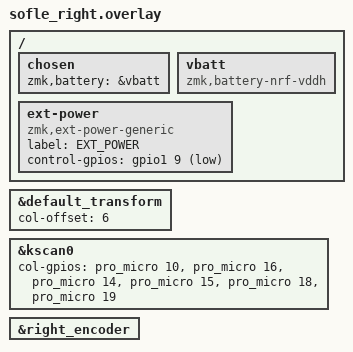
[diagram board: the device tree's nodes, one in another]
/*
 * Copyright (c) 2020 Ryan Cross
 *
 * SPDX-License-Identifier: MIT
 */

#include "sofle.dtsi"

&default_transform {
    col-offset = <6>;
};

&kscan0 {
    col-gpios
        = <&pro_micro 10 GPIO_ACTIVE_HIGH>
        , <&pro_micro 16 GPIO_ACTIVE_HIGH>
        , <&pro_micro 14 GPIO_ACTIVE_HIGH>
        , <&pro_micro 15 GPIO_ACTIVE_HIGH>
        , <&pro_micro 18 GPIO_ACTIVE_HIGH>
        , <&pro_micro 19 GPIO_ACTIVE_HIGH>
        ;
};

&right_encoder {
    status = "okay";
};
/ {
    chosen {
      zmk,battery = &vbatt;
    };

    vbatt: vbatt {
        compatible = "zmk,battery-nrf-vddh";
    };
};

/ {
    ext-power {
        compatible = "zmk,ext-power-generic";
        label = "EXT_POWER";
        // Aquí está el truco: GPIO_ACTIVE_LOW
        // Esto le dice a ZMK: "Cuando quieras ENCENDER, pon el pin en 0".
        control-gpios = <&gpio1 9 GPIO_ACTIVE_LOW>;
    };
};

